AUTOSAR XML (schema 4-0-3)
standard types defined: UInt16, UInt32
package /AUTOSAR_Platform/DataConstrs
  range DC_UInt16: raw 0..65535
package /PATAC/MSM/ComponentTypes
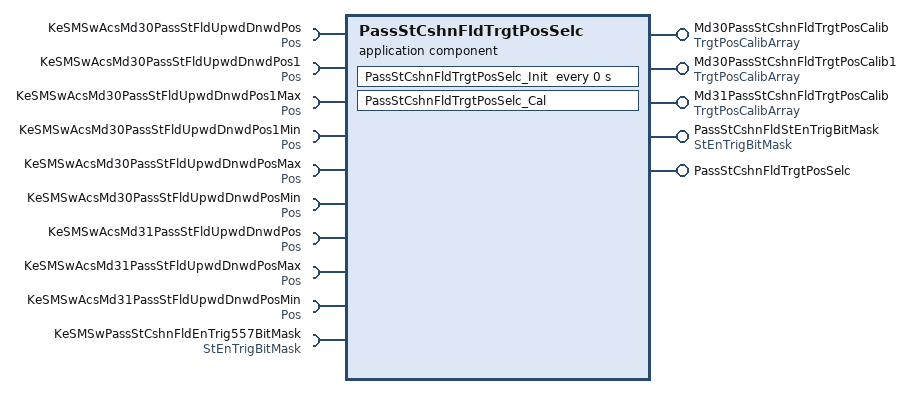
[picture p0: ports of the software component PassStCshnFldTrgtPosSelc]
  application sw component type PassStCshnFldTrgtPosSelc
    5 x provide port:
      Md30PassStCshnFldTrgtPosCalib: nonqueued-sender-com-spec{data-element=TrgtPosArray, init-value=[4095, 4095, 4095]}, provided-interface=TrgtPosCalibArray
      Md30PassStCshnFldTrgtPosCalib1: nonqueued-sender-com-spec{data-element=TrgtPosArray, init-value=[4095, 4095, 4095]}, provided-interface=TrgtPosCalibArray
      Md31PassStCshnFldTrgtPosCalib: nonqueued-sender-com-spec{data-element=TrgtPosArray, init-value=[4095, 4095, 4095]}, provided-interface=TrgtPosCalibArray
      PassStCshnFldStEnTrigBitMask: nonqueued-sender-com-spec{data-element=Val, init-value=0}, provided-interface=StEnTrigBitMask
      PassStCshnFldTrgtPosSelc: server-com-spec{operation=Cal, queue-length=1}, provided-interface=PassStCshnFldTrgtPosSelc
    10 x require port:
      KeSMSwAcsMd30PassStFldUpwdDnwdPos: parameter-require-com-spec{init-value=0, parameter=Pos/Val}, required-interface=Pos
      KeSMSwAcsMd30PassStFldUpwdDnwdPos1: parameter-require-com-spec{init-value=0, parameter=Pos/Val}, required-interface=Pos
      KeSMSwAcsMd30PassStFldUpwdDnwdPos1Max: parameter-require-com-spec{init-value=0, parameter=Pos/Val}, required-interface=Pos
      KeSMSwAcsMd30PassStFldUpwdDnwdPos1Min: parameter-require-com-spec{init-value=0, parameter=Pos/Val}, required-interface=Pos
      KeSMSwAcsMd30PassStFldUpwdDnwdPosMax: parameter-require-com-spec{init-value=0, parameter=Pos/Val}, required-interface=Pos
      KeSMSwAcsMd30PassStFldUpwdDnwdPosMin: parameter-require-com-spec{init-value=0, parameter=Pos/Val}, required-interface=Pos
      KeSMSwAcsMd31PassStFldUpwdDnwdPos: parameter-require-com-spec{init-value=0, parameter=Pos/Val}, required-interface=Pos
      KeSMSwAcsMd31PassStFldUpwdDnwdPosMax: parameter-require-com-spec{init-value=0, parameter=Pos/Val}, required-interface=Pos
      KeSMSwAcsMd31PassStFldUpwdDnwdPosMin: parameter-require-com-spec{init-value=0, parameter=Pos/Val}, required-interface=Pos
      KeSMSwPassStCshnFldEnTrig557BitMask: parameter-require-com-spec{init-value=6153, parameter=StEnTrigBitMask/Val}, required-interface=StEnTrigBitMask
    behavior PassStCshnFldTrgtPosSelc_InternalBehavior
      operation invoked event OIT_PassStCshnFldTrgtPosSelc_Cal_PassStCshnFldTrgtPosSelc_Cal: start-on-event=PassStCshnFldTrgtPosSelc_Cal, operation=PassStCshnFldTrgtPosSelc.Cal
      timing event PassStCshnFldTrgtPosSelc_InitEvent: start-on-event=PassStCshnFldTrgtPosSelc_Init, period=0
      runnable PassStCshnFldTrgtPosSelc_Cal
        data-send-points:
          4 x access:
            SEND_Md30PassStCshnFldTrgtPosCalib_TrgtPosArray: accessed-variable=Md30PassStCshnFldTrgtPosCalib.TrgtPosArray
            SEND_Md30PassStCshnFldTrgtPosCalib1_TrgtPosArray: accessed-variable=Md30PassStCshnFldTrgtPosCalib1.TrgtPosArray
            SEND_Md31PassStCshnFldTrgtPosCalib_TrgtPosArray: accessed-variable=Md31PassStCshnFldTrgtPosCalib.TrgtPosArray
            SEND_PassStCshnFldStEnTrigBitMask_Val: accessed-variable=PassStCshnFldStEnTrigBitMask.Val
        10 x parameter access:
          PA_KeSMSwAcsMd30PassStFldUpwdDnwdPos_Val: accessed-parameter=KeSMSwAcsMd30PassStFldUpwdDnwdPos.Val
          PA_KeSMSwAcsMd30PassStFldUpwdDnwdPos1_Val: accessed-parameter=KeSMSwAcsMd30PassStFldUpwdDnwdPos1.Val
          PA_KeSMSwAcsMd30PassStFldUpwdDnwdPos1Max_Val: accessed-parameter=KeSMSwAcsMd30PassStFldUpwdDnwdPos1Max.Val
          PA_KeSMSwAcsMd30PassStFldUpwdDnwdPos1Min_Val: accessed-parameter=KeSMSwAcsMd30PassStFldUpwdDnwdPos1Min.Val
          PA_KeSMSwAcsMd30PassStFldUpwdDnwdPosMax_Val: accessed-parameter=KeSMSwAcsMd30PassStFldUpwdDnwdPosMax.Val
          PA_KeSMSwAcsMd30PassStFldUpwdDnwdPosMin_Val: accessed-parameter=KeSMSwAcsMd30PassStFldUpwdDnwdPosMin.Val
          PA_KeSMSwAcsMd31PassStFldUpwdDnwdPos_Val: accessed-parameter=KeSMSwAcsMd31PassStFldUpwdDnwdPos.Val
          PA_KeSMSwAcsMd31PassStFldUpwdDnwdPosMax_Val: accessed-parameter=KeSMSwAcsMd31PassStFldUpwdDnwdPosMax.Val
          PA_KeSMSwAcsMd31PassStFldUpwdDnwdPosMin_Val: accessed-parameter=KeSMSwAcsMd31PassStFldUpwdDnwdPosMin.Val
          PA_KeSMSwPassStCshnFldEnTrig557BitMask_Val: accessed-parameter=KeSMSwPassStCshnFldEnTrig557BitMask.Val
      runnable PassStCshnFldTrgtPosSelc_Init
        10 x parameter access:
          PA_KeSMSwAcsMd30PassStFldUpwdDnwdPos_Val: accessed-parameter=KeSMSwAcsMd30PassStFldUpwdDnwdPos.Val
          PA_KeSMSwAcsMd30PassStFldUpwdDnwdPos1_Val: accessed-parameter=KeSMSwAcsMd30PassStFldUpwdDnwdPos1.Val
          PA_KeSMSwAcsMd30PassStFldUpwdDnwdPos1Max_Val: accessed-parameter=KeSMSwAcsMd30PassStFldUpwdDnwdPos1Max.Val
          PA_KeSMSwAcsMd30PassStFldUpwdDnwdPos1Min_Val: accessed-parameter=KeSMSwAcsMd30PassStFldUpwdDnwdPos1Min.Val
          PA_KeSMSwAcsMd30PassStFldUpwdDnwdPosMax_Val: accessed-parameter=KeSMSwAcsMd30PassStFldUpwdDnwdPosMax.Val
          PA_KeSMSwAcsMd30PassStFldUpwdDnwdPosMin_Val: accessed-parameter=KeSMSwAcsMd30PassStFldUpwdDnwdPosMin.Val
          PA_KeSMSwAcsMd31PassStFldUpwdDnwdPos_Val: accessed-parameter=KeSMSwAcsMd31PassStFldUpwdDnwdPos.Val
          PA_KeSMSwAcsMd31PassStFldUpwdDnwdPosMax_Val: accessed-parameter=KeSMSwAcsMd31PassStFldUpwdDnwdPosMax.Val
          PA_KeSMSwAcsMd31PassStFldUpwdDnwdPosMin_Val: accessed-parameter=KeSMSwAcsMd31PassStFldUpwdDnwdPosMin.Val
          PA_KeSMSwPassStCshnFldEnTrig557BitMask_Val: accessed-parameter=KeSMSwPassStCshnFldEnTrig557BitMask.Val
  swc implementation PassStCshnFldTrgtPosSelc_Implementation: behavior=PassStCshnFldTrgtPosSelc_InternalBehavior
    code-descriptors:
      code Default: artifact-descriptors=autosar-engineering-object={short-label=Default, category=SWSRC}
package /PATAC/MSM/ModeAdjust/CalPortInterface
  parameter interface Pos
    parameter data prototype Val: sw-calibration-access=READ-WRITE, type=UInt16
  parameter interface StEnTrigBitMask
    parameter data prototype Val: sw-calibration-access=READ-WRITE, type=UInt32
package /PATAC/MSM/ModeAdjust/DataType
  impl type TrgtPosCalibArray: category=ARRAY, sw-calibration-access=READ-ONLY, type-emitter=RTE  # 0:pos 1:max 2:min
    element Element: array-size=3, array-size-semantics=FIXED-SIZE, implementation-data-type=UInt16, invalid-value=0
package /PATAC/MSM/ModeAdjust/PortInterface
  client server interface PassStCshnFldTrgtPosSelc
    operation Cal
  sender receiver interface StEnTrigBitMask: invalidation-policy{data-element=Val, handle-invalid=DONT-INVALIDATE}
    data Val: type=UInt32
  sender receiver interface TrgtPosCalibArray: invalidation-policy{data-element=TrgtPosArray, handle-invalid=DONT-INVALIDATE}
    data TrgtPosArray: type=TrgtPosCalibArray  # 0:Pos 1:Max 2:Min
